# AE1C1F4051920PH0_CM55_HE_View register map
Vendor: Alif Semiconductor; Series: E1; File version: 1.0
CPU: CM55 r1p0, selectable endian, MPU, FPU, double-precision FPU, DSP, VTOR, 8 interrupt priority bits, 1 SAU regions
Registers are 32-bit, read-write, reset 0x0 unless marked. A register's access mark holds for its fields unless they carry their own. Offsets are from the block's base; [hi:lo] are bit positions; {n}, {i} and the like mark numbered series; <NAME> marks a mode.

## CANFD0
Base 0x49036000
Same registers: CANFD1 0x49038000
{0x0+4i} CANFD_RBUF[{i}] (i=0..19) ro — Receive Buffer Register
  [31:0] RBUF
{0x50+4i} CANFD_TBUF[{i}] (i=0..17) — Transmit Buffer Register
  [31:0] TBUF
0x98 CANFD_TTS ro — Transmission Time Stamp Register
  [31:0] TTS — Transmission Time Stamp. This bit field holds the time-stamp of the last transmitted frame for CiA 603 time stamping. Every new frame overwrites it if the TTSEN field of TBUF register is 0x1. The TTS bit field is intended to be used by the time master to acquire the time-stamp of the SYNC message.
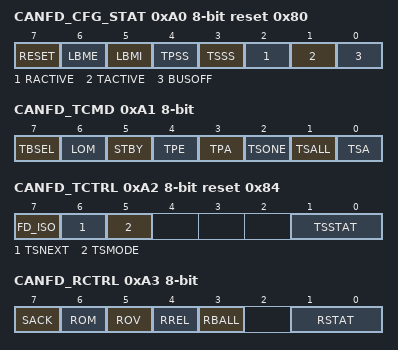
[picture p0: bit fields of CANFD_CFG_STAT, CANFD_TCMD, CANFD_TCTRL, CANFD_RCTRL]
0xA0 CANFD_CFG_STAT 8-bit reset 0x80 — Configuration and Status Register
  [7] RESET — RESET Request Bit. Some registers can only be modified if the RESET bit is set to 0x1. This bit forces several components to a reset state. A detailed definition is given in Section Software Reset. It is automatically set if the node enters bus off state (refer to Section Error Handling). Note that a CAN node will participate in CAN communication after the RESET bit is switched to 0x0 after 11 CAN bit times. This delay is required by the CAN standard (bus idle time). If the RESET bit is set to 0x1 and immediately set to 0x0, then it takes some time until it can be read as 0x0 and becomes inactive. The reason is clock domain crossing from host to CAN clock domain. The RESET bit is held active as long as needed depending on the relation between host and CAN clock.
    0=No local reset of the CAN controller; 1=The host controller performs a local reset of the CAN controller
  [6] LBME — Loop Back Mode, External (refer to Section Loop Back Mode (LBMI and LBME)). Note that this bit should not be enabled while a transmission is active.
    0=Disabled; 1=Enabled
  [5] LBMI — Loop Back Mode, Internal (refer to Section Loop Back Mode (LBMI and LBME)). Note that this bit should not be enabled while a transmission is active.
    0=Disabled; 1=Enabled
  [4] TPSS — Transmission Primary Single Shot Mode for PTB (refer to Section Single Shot Transmission (SST)).
    0=Disabled; 1=Enabled
  [3] TSSS — Transmission Secondary Single Shot Mode for STB (refer to Section Single Shot Transmission (SST)).
    0=Disabled; 1=Enabled
  [2] RACTIVE ro — Reception ACTIVE (Receive Status Bit).
    0=No receive activity; 1=The controller is currently receiving a frame
  [1] TACTIVE ro — Transmission ACTIVE (Transmit Status Bit).
    0=No transmit activity; 1=The controller is currently transmitting a frame
  [0] BUSOFF — Bus Off (Bus Status Bit, refer to Section Error Handling). Writing a 0x1 to this bit will reset the CANFD_TECNT and CANFD_RECNT registers. This should be done only for debugging. For more details, refer Section Error Counter Reset.
    0=The controller status is bus on; 1=The controller status is bus off
0xA1 CANFD_TCMD 8-bit — Command Register
  [7] TBSEL — Transmit Buffer Select. Selects the transmit buffer to be loaded with a message. Use the TBUF registers for access. The TBSEL bit needs to be stable all the time the TBUF registers are written and when the CANFD_TCTRL[TSNEXT] bit is set.
    0=PTB (high-priority buffer); 1=STB
  [6] LOM — Listen Only Mode (refer to Section Listen Only Mode (LOM)). This bit cannot be set if the TPE, TSONE, or TSALL bit is set. No transmission can be started if it is enabled and the CANFD_CFG_STAT[LBME] bit is disabled. The LOM = 0x1 and CANFD_CFG_STAT[LBME] = 0x0 disables all transmissions. The LOM = 0x1 and CANFD_CFG_STAT[LBME] = 0x1 disables the ACK for received frames and error frames, but enables the transmission of own frames.
    0=Disabled; 1=Enabled
  [5] STBY — Transceiver Standby Mode (refer to Section Transceiver Standby Mode). This register bit can be used to control a standby mode of a transceiver. This bit cannot be set to 0x1 if the TPE, TSONE, or TSALL bit is set to 0x1. If the host sets it to 0x0 then the host needs to wait for the time required by the transceiver to start up before the host requests a new transmission.
    0=Disabled; 1=Enabled
  [4] TPE — Transmit Primary Enable. If this bit is set, the message from the PTB will be transmitted at the next possible transmit position. A started transmission from the STB will be completed before, but pending new messages are delayed until the PTB message has been transmitted. The TPE bit stays set until the message has been transmitted successfully or it is aborted using the TPA bit. The host controller can set the TPE bit to 0x1 but can not reset it to 0x0. This would only be possible using the TPA bit and aborting the message. The bit will be reset to the hardware reset value if the CANFD_CFG_STAT[RESET] = 0x1, STBY = 0x1, (LOM = 0x1 and CANFD_CFG_STAT[LBME] = 0x0).
    0=No transmission for the PTB; 1=Transmission enable for the message in the high-priority PTB
  [3] TPA — Transmit Primary Abort. The bit has to be set by the host controller and will be reset by the CAN controller. Setting this bit automatically de-asserts the TPE bit. The host controller can set the TPA bit to 0x1 but can not reset it to 0x0. During the short time while the CAN controller resets the bit, it cannot be set by the host. The bit will be reset to the hardware reset value if the CANFD_CFG_STAT[RESET] = 0x1. This bit should not be set simultaneously with the TPE bit.
    0=No abort; 1=Aborts a transmission from PTB which has been requested by the TPE = 0x1 but not started yet (the data bytes of the message remains in the PTB)
  [2] TSONE — Transmit Secondary One Frame. This bit in priority mode is difficult to handle, because it is not always clear which message will be transmitted if new messages are written to the STB meanwhile. The controller starts the transmission as soon as the bus becomes vacant and no request of the PTB (the TPE bit) is pending. The TSONE bit stays set until the message has been transmitted successfully or it is aborted using the TSA bit. The host controller can set the TSONE bit to 0x1 but can not reset it to 0x0. This would only be possible using the TSA bit and aborting the message. The bit will be reset to the hardware reset value if the CANFD_CFG_STAT[RESET] = 0x1, STBY = 0x1, (LOM = 0x1 and CANFD_CFG_STAT[LBME] = 0x0).
    0=No transmission for the STB; 1=Transmission enable of one in the STB. In FIFO mode this is the oldest message and in priority mode this is the one with the highest priority
  [1] TSALL — Transmit Secondary All Frames. The controller starts the transmission as soon as the bus becomes vacant and no request of the PTB (the TPE bit) is pending. This bit stays set until all messages have been transmitted successfully or they are aborted using the TSA bit. The host controller can set the TSALL bit to 0x1 but can not reset it to 0x0. This would only be possible using the TSA bit and aborting the messages. The bit will be reset to the hardware reset value if the CANFD_CFG_STAT[RESET] = 0x1, STBY = 0x1, (LOM = 0x1 and CANFD_CFG_STAT[LBME] = 0x0). If during a transmission the STB is loaded with a new frame then the new frame will be transmitted too. In other words: a transmission initiated by this bit is finished when the STB becomes empty. Note: Setting both TSONE and TSALL bits is meaningless. While the TSALL bit is already set, it is impossible to set the TSONE bit and vice versa. If both TSONE and TSALL bits are set simultaneously then the TSALL bit wins and the TSONE bit is cleared by the CAN controller.
    0=No transmission for the STB; 1=Transmission enable of all messages in the STB
  [0] TSA — Transmit Secondary Abort. The bit has to be set by the host controller and will be reset by the CAN controller. Setting this bit, automatically de-asserts the TSONE or TSALL bit respectively. The host controller can set this bit to 0x1 but can not reset it to 0x0. The bit will be reset to the hardware reset value if the CANFD_CFG_STAT[RESET] = 0x1. This bit should not be set simultaneously with the TSONE or TSALL bit. For a TSONE transmission, only one frame is aborted while for a TSALL transmission, all frames are aborted. One or all message slots will be released which updates the CANFD_TCTRL[TSSTAT] bit field. All aborted messages are lost because they are not accessible any more. If in priority mode a TSONE transmission is aborted, then it is not clear which frame will be aborted if new frames are written to the STB meanwhile.
    0=No abort; 1=Aborts a transmission from STB which has been requested but not started yet
0xA2 CANFD_TCTRL 8-bit reset 0x84 — Transmit Control Register
  [7] FD_ISO — CAN FD ISO Mode. ISO CAN FD mode has a different CRC initialization value and an additional stuff bit count. Both modes are incompatible and must not be mixed in one CAN network. This bit has no impact to CAN 2.0B. This bit is only writeable if the CANFD_CFG_STAT[RESET] = 0x1.
    0=Bosch CAN FD (non-ISO) mode; 1=ISO CAN FD mode (ISO 11898-1:2015)
  [6] TSNEXT — Transmit Buffer Secondary Next. After all frame bytes are written to the TBUF registers, the host controller has to set this bit to signal that this slot has been filled. Then the CAN controller connects the TBUF registers to the next slot. Once a slot is marked as filled a transmission can be started using the CANFD_TCMD[TSONE] or CANFD_TCMD[TSALL] bit. It is possible to set the TSNEXT bit and the CANFD_TCMD[TSONE] or CANFD_TCMD[TSALL] bit together in one write access. This bit has to be set by the host controller and is automatically reset by the CAN controller immediately after it was set. Setting the TSNEXT bit is meaning less if the CANFD_TCMD[TBSEL] = 0x0. In this case the TSNEXT bit is ignored and automatically cleared. It does not do any harm. If all slots of the STB are filled, this bit stays set until a slot becomes free (refer to Section Full STB).
    0=No action; 1=STB slot filled, select next slot
  [5] TSMODE — Transmit Buffer Secondary Operation Mode. In FIFO mode frames are transmitted in the order in that they are written into the STB. In priority decision mode the frame with the highest priority in the STB is automatically transmitted first. The ID of a frame is used for the priority decision. A lower ID means a higher priority of a frame. A frame in the PTB has always the highest priority regardless of the ID. This bit shall be switched only if the STB is empty.
    0=FIFO mode; 1=Priority decision mode
  [1:0] TSSTAT ro — Transmission Secondary Status Bits.
    0=STB is empty; 1=STB is less than or equal to half full; 2=STB is more than half full; 3=STB is full
0xA3 CANFD_RCTRL 8-bit — Receive Control Register
  [7] SACK — Self-Acknowledge.
    0=No self-ACK; 1=Self-ACK when the CANFD_CFG_STAT[LBME] = 0x1
  [6] ROM — Receive Buffer Overflow Mode. In case of a full RBUF when a new message is received, then this bit selects the following:
    0=The oldest message will be overwritten; 1=The new message will not be stored
  [5] ROV ro — Receive Buffer Overflow. This bit is cleared by setting the RREL = 0x1.
    0=No Overflow; 1=Overflow. At least one message is lost
  [4] RREL — Receive Buffer Release. The host controller has read the actual RB slot and releases it. Afterwards the CAN controller points to the next RB slot. The RSTAT bit field gets updated.
    0=No release; 1=Release: The host has read the RB
  [3] RBALL — Receive Buffer Stores All Data Frames.
    0=Normal operation; 1=RB stores correct data frames as well as data frames with error (refer to Section Reception of All Data Frames (CANFD_RCTRL[RBALL]))
  [1:0] RSTAT ro — Receive Buffer Status.
    0=Empty; 1=> Empty and < almost full (CANFD_LIMIT[AFWL]); 2=Almost full (programmable threshold by the CANFD_LIMIT[AFWL] bit field) but not full and no overflow; 3=Full (stays set in case of overflow-for overflow signaling, see the ROV bit)
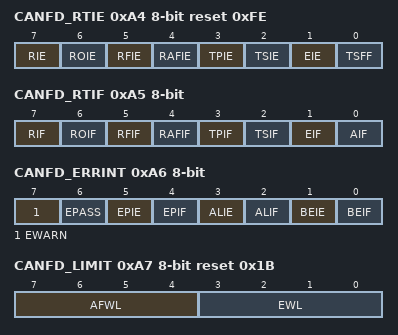
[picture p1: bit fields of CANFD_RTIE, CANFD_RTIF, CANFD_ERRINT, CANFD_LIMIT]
0xA4 CANFD_RTIE 8-bit reset 0xFE — Receive and Transmit Interrupt Enable Register
  [7] RIE — Receive Interrupt Enable.
    0=Disabled; 1=Enabled
  [6] ROIE — RB Overrun Interrupt Enable.
    0=Disabled; 1=Enabled
  [5] RFIE — RB Full Interrupt Enable.
    0=Disabled; 1=Enabled
  [4] RAFIE — RB Almost Full Interrupt Enable.
    0=Disabled; 1=Enabled
  [3] TPIE — Transmission Primary Interrupt Enable.
    0=Disabled; 1=Enabled
  [2] TSIE — Transmission Secondary Interrupt Enable.
    0=Disabled; 1=Enabled
  [1] EIE — Error Interrupt Enable.
    0=Disabled; 1=Enabled
  [0] TSFF ro — Transmit Secondary Buffer Full Flag.
    0=The STB is not filled with the maximal number of messages; 1=The STB is filled with the maximal number of messages
0xA5 CANFD_RTIF 8-bit — Receive and Transmit Interrupt Flag Register
  [7] RIF write-1-clears — Receive Interrupt Flag.
    0=No frame has been received; 1=Data or a remote frame has been received and is available in the receive buffer
  [6] ROIF write-1-clears — RB Overrun Interrupt Flag. In case of an overrun both ROIF and RFIF bits are set.
    0=No RB overwritten; 1=At least one received message has been overwritten in the RB
  [5] RFIF write-1-clears — RB Full Interrupt Flag.
    0=The RB FIFO is not full; 1=All RBs are full. If no RB is released until the next valid message is received, the oldest message is lost
  [4] RAFIF write-1-clears — RB Almost Full Interrupt Flag. Refer to the CANFD_LIMIT[AFWL] bit field.
    0=number of filled RB slots < AFWL_i; 1=number of filled RB slots AFWL_i
  [3] TPIF write-1-clears — Transmission Primary Interrupt Flag.
    0=No transmission of the PTB has been completed; 1=The requested transmission of the PTB has been successfully completed
  [2] TSIF write-1-clears — Transmission Secondary Interrupt Flag.
    0=No transmission of the STB has been completed successfully; 1=The requested transmission of the STB has been successfully completed
  [1] EIF write-1-clears — Error Interrupt Flag.
    0=There has been no change; 1=The border of the error warning limit has been crossed in either direction, or the CANFD_CFG_STAT[BUSOFF] bit has been changed in either direction
  [0] AIF write-1-clears — Abort Interrupt Flag. It is recommended to not set both CANFD_TCMD[TPA] and CANFD_TCMD[TSA] bits simultaneously because both source this bit. This bit does not have an associated enable register. Refer to Section Message Transmission Abort.
    0=No abort has been executed; 1=After setting the CANFD_TCMD[TPA] or CANFD_TCMD[TSA] bit the appropriated message(s) have been aborted
0xA6 CANFD_ERRINT 8-bit — Error Interrupt Enable and Flag Register
  [7] EWARN ro — Error Warning Limit Reached.
    0=The values in both counters are less than the CANFD_LIMIT[EWL] bit field; 1=One of the error counters (the CANFD_RECNT or CANFD_TECNT register) is equal or bigger than the CANFD_LIMIT[EWL] bit field
  [6] EPASS ro — Error Passive Mode Active.
    0=Not active (node is error active); 1=Active (node is error passive)
  [5] EPIE — Error Passive Interrupt Enable.
  [4] EPIF write-1-clears — Error Passive Interrupt Flag. This bit will be activated if the error status changes from error active to error passive or vice versa and if this interrupt is enabled.
  [3] ALIE — Arbitration Lost Interrupt Enable.
  [2] ALIF write-1-clears — Arbitration Lost Interrupt Flag.
  [1] BEIE — Bus Error Interrupt Enable.
  [0] BEIF write-1-clears — Bus Error Interrupt Flag.
0xA7 CANFD_LIMIT 8-bit reset 0x1B — Warning Limits Register
  [7:4] AFWL — Almost Full Warning Limit. The AFWL bit field defines the internal warning limit AFWL_i with nRB being the number of available RB slots. AFWL_i is compared to the number of filled RB slots and triggers the CANFD_RTIF[RAFIF] bit if equal. The valid range of AFWL_i is [1KB nRB]. AFWL = 0 is meaningless and automatically treated as 0x1. Note that AFWL is meant in this rule and not AFWL_i. AFWL_i > nRB is meaningless and automatically treated as nRB. AFWL_i = nRB is a valid value, but note that the CANFD_RTIF[RFIF] bit also exists.
  [3:0] EWL — Programmable Error Warning Limit = (EWL + 1) x 8. Possible Limit values: 8, 16, ...128. The value of this bit field controls the CANFD_RTIF[EIF] bit. The EWL bit field needs to be transferred using Clock Domain Crossing (CDC) from host to CAN clock domain. During transfer, this bit field is write-locked for the host for a few clocks until CDC is complete.
0xA8 CANFD_S_SEG_1 8-bit reset 0x3 — Slow Speed Bit Timing 1 Register (Segment 1)
  [7:0] S_SEG_1 — Bit Timing Segment 1 (Slow Speed). The sample point will be set to tSeg_1 = (Seg_1 + 2) x TQ after start of bit time.
0xA9 CANFD_S_SEG_2 8-bit reset 0x2 — Slow Speed Bit Timing 2 Register (Segment 2)
  [6:0] S_SEG_2 — Bit Timing Segment 2 (Slow Speed). Time tSeg_2 = (Seg_2 + 1) x TQ after the sample point.
0xAA CANFD_S_SJW 8-bit reset 0x2 — Slow Speed Bit Timing 3 Register (Synchronization Jump Width)
  [6:0] S_SJW — Synchronization Jump Width (Slow Speed). The Synchronization Jump Width tSJW = (SJW + 1) x TQ is the maximum time for shortening or lengthening the Bit Time for resynchronization, where TQ is a time quanta.
0xAB CANFD_S_PRESC 8-bit reset 0x1 — Slow Speed Prescaler Register
  [7:0] S_PRESC — Prescaler Slow Speed. The prescaler divides the system clock to get the time quanta clock. Valid range for the CANFD_S_PRESC[S_PRESC] bit field is from 0x00 to 0xFF (results in divider values from 1 to 255).
0xAC CANFD_F_SEG_1 8-bit reset 0x3 — Fast Speed Bit Timing 1 Register (Segment 1)
  [4:0] F_SEG_1 — Bit Timing Segment 1 (Fast Speed). The sample point will be set to tSeg_1 = (Seg_1 + 2) x TQ after start of bit time.
0xAD CANFD_F_SEG_2 8-bit reset 0x2 — Fast Speed Bit Timing 2 Register (Segment 2)
  [3:0] F_SEG_2 — Bit Timing Segment 2 (Fast Speed). Time tSeg_2 = (Seg_2 + 1) x TQ after the sample point.
0xAE CANFD_F_SJW 8-bit reset 0x2 — Fast Speed Bit Timing 3 Register (Synchronization Jump Width)
  [3:0] F_SJW — Synchronization Jump Width (Fast Speed). The Synchronization Jump Width tSJW = (SJW + 1) x TQ is the maximum time for shortening or lengthening the Bit Time for resynchronization, where TQ is a time quanta.
0xAF CANFD_F_PRESC 8-bit reset 0x1 — Fast Speed Prescaler Register
  [7:0] F_PRESC — Prescaler Fast Speed. The prescaler divides the system clock to get the time quanta clock. Valid range for the CANFD_F_PRESC[F_PRESC] bit field is from 0x00 to 0xFF (results in divider values from 1 to 255).
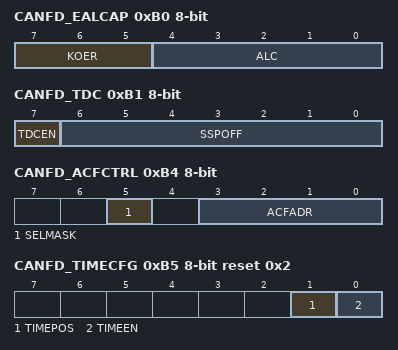
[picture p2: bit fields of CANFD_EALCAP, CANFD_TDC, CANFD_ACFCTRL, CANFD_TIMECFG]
0xB0 CANFD_EALCAP 8-bit ro — Error and Arbitration Lost Capture Register
  [7:5] KOER — Kind of Error (Error Code). (dominant bits after own error flag, received active Error Flag too long, dominant bit during Passive-Error-Flag after ACK error) This bit field is updated with each new error. Therefore, it stays untouched when frames are successfully transmitted or received.
    0=No error; 1=BIT ERROR; 2=FORM ERROR; 3=STUFF ERROR; 4=ACKNOWLEDGEMENT ERROR; 5=CRC ERROR; 6=OTHER ERROR
  [4:0] ALC — Arbitration Lost Capture (bit position in the frame where the arbitration has been lost)
0xB1 CANFD_TDC 8-bit — Transmitter Delay Compensation Register
  [7] TDCEN — Transmitter Delay Compensation Enable. The Transmitter Delay Compensation (TDC) will be activated during the data phase of a CAN FD frame if BRS is active and if the TDCEN = 0x1. For more details about TDC refer to Section Bit Rate Switching and Sample Point.
  [6:0] SSPOFF — Secondary Sample Point Offset. The transmitter delay plus defines the time of the secondary sample point for TDC (the SSPOFF bit field value is given as a number of TQ).
0xB2 CANFD_RECNT 8-bit ro — Receive Error Counter Register
  [7:0] RECNT — Receive Error Count (Number of Errors During Reception). This bit field is incremented and decremented as defined in the CAN specification. The CANFD_RECNT register does not overflow. For more details about the CANFD_RECNT register and the bus off state, refer to Section Error Handling.
0xB3 CANFD_TECNT 8-bit ro — Transmit Error Counter Register
  [7:0] TECNT — Transmit Error Count (Number of Errors During Transmission). This bit field is incremented and decremented as defined in the CAN specification. In case of the bus off state, the TECNT bit field may overflow. For more details about this bit field and the bus off state, refer to Section Error Handling.
0xB4 CANFD_ACFCTRL 8-bit — Acceptance Filter Control Register
  [5] SELMASK — Select Acceptance MASK. The ACFADR bit field selects one specific acceptance filter.
    0=The ACF_X registers (where X = 1 to 3) point to acceptance code; 1=The ACF_X registers (where X = 1 to 3) point to acceptance mask
  [3:0] ACFADR — Acceptance Filter Address. This bit field points to a specific acceptance filter. The selected filter is accessible using the ACF_X registers (where X = 1 to 3). The SELMASK bit selects between acceptance code and mask for the selected acceptance filter. A value of the ACFADR bit field > Number of Acceptance Filters (NAF) - 1 is meaningless and automatically treated as value NAF - 1.
0xB5 CANFD_TIMECFG 8-bit reset 0x2 — CiA 603 Time-Stamping Register
  [1] TIMEPOS — Time-Stamping Position. For description of the SOF and EOF bits, refer to Section Table 1-2 CAN Bit Abbreviations. This bit can only be changed if the TIMEEN = 0x0, but it is possible to modify it with the same write access that sets the TIMEEN = 0x1.
    0=SOF; 1=EOF
  [0] TIMEEN — Time-Stamping Enable.
    0=Disabled; 1=Enabled
0xB6 CANFD_ACF_EN_0 8-bit reset 0x1 — Acceptance Filter Enable 0 Register
  [7:0] AE_X — Acceptance Filter Enable. Each acceptance filter (AMASK/ACODE) can be individually enabled or disabled. Only filter number 0 is enabled by default after hardware reset. Disabled filters reject a message. Only enabled filters can accept a message if the appropriate AMASK/ACODE configuration matches. To accept all messages one filter x has to be enabled by setting AE_X = 0x1, AMASK_X = 0xFF and ACODE_X = 0x00. This is the default configuration after hardware reset for filter X = 0 while all other filters are disabled.
    0=Acceptance filter disable; 1=Acceptance filter enabled
0xB7 CANFD_ACF_EN_1 8-bit — Acceptance Filter Enable 1 Register
  [7:0] AE_X — Acceptance Filter Enable. Each acceptance filter (AMASK/ACODE) can be individually enabled or disabled. Disabled filters reject a message. Only enabled filters can accept a message if the appropriate AMASK/ACODE configuration matches.
    0=Acceptance filter disable; 1=Acceptance filter enabled
0xB8 CANFD_ACF_0_3_CODE — Acceptance CODE Register
  [28:0] ACODE_X — Acceptance CODE. The ID bits are compared with the corresponding acceptance code bits as follows: - ACODE_X(10-0) will be used for standard frames. - ACODE_X(28-0) will be used for extended frames. Only filter 0 is affected by the power-on reset. All other filters stay uninitialized. Refer to Section Software Reset.
    0=Acceptance code bit value to compare with ID bit of the received message is disabled; 1=Acceptance code bit value to compare with ID bit of the received message is enabled
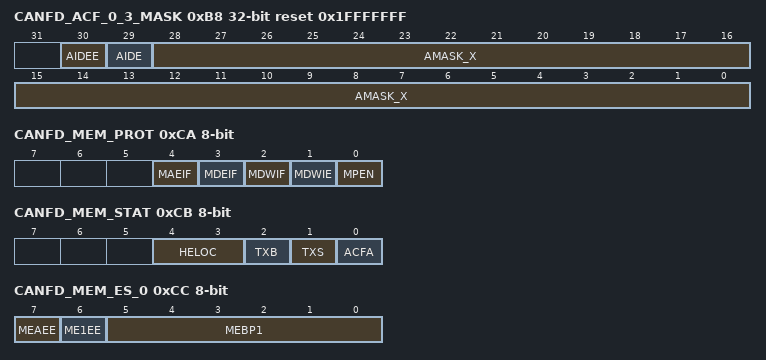
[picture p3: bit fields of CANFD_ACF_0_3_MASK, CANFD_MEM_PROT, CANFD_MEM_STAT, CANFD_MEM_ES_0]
0xB8 CANFD_ACF_0_3_MASK reset 0x1FFFFFFF (alternate view of CANFD_ACF_0_3_CODE) — Acceptance MASK Register
  [30] AIDEE — Acceptance Mask IDE Bit Check Enable. Only filter 0 is affected by the power-on reset. All other filters stay uninitialized.
    0=Acceptance filter accepts both standard or extended frames; 1=Acceptance filter accepts either standard or extended as defined by this bit
  [29] AIDE — Acceptance Mask IDE Bit Value. If the AIDEE = 0x1 then: Only filter 0 is affected by the power-on reset. All other filters stay uninitialized. Note: The AIDEE and AIDE bits can only be accessed if the CANFD_ACFCTRL[SELMASK] = 0x1. These bits can be used to accept only either standard or extended frames with the selected ACODE / AMASK setting or to accept both frame types. Only acceptance filter 0 is affected by the power-on reset and it is configured to accept both frame types after power-up.
    0=Acceptance filter accepts only standard frames; 1=Acceptance filter accepts only extended frames
  [28:0] AMASK_X — Acceptance MASK 3. - AMASK_X(10-0) will be used for standard frames. - AMASK_X(28-0) will be used for extended frames. Disabled bits result in accepting the message. Therefore, the default configuration after reset for filter 0 accepts all messages. Only filter 0 is affected by the power-on reset. All other filters stay uninitialized. Refer to Section Software Reset.
    0=Acceptance check for these bits of receive identifier enable; 1=Acceptance check for these bits of receive identifier disabled
0xBC CANFD_VER_0 8-bit ro reset 0x9 — Version Information 0 Register
  [7:0] VER_0 — Version (minor) [7-0]
0xBD CANFD_VER_1 8-bit ro reset 0x7 — Version Information 1 Register
  [7:0] VER_1 — Version (major) [15-0]
0xCA CANFD_MEM_PROT 8-bit — Memory Protection Register
  [4] MAEIF — Memory: Address Error Interrupt Flag. This bit will be set if memory protection has detected an error in the address. The error was not corrected.
  [3] MDEIF — Memory: Data Error Interrupt Flag. This bit will be set if memory protection has detected an error in the data which was not correctable.
  [2] MDWIF — Memory: Data Warning Interrupt Flag. This bit will be set if the MDWIE bit is set and memory protection has detected an error in the data which has been automatically corrected. The system continues operation.
  [1] MDWIE — Memory: Data Warning Interrupt Enable.
    0=Disabled; 1=Enabled
  [0] MPEN — Memory Protection Enable. This bit is only writable if the CANFD_CFG_STAT[RESET] = 0x1.
    0=Disabled; 1=Enabled
0xCB CANFD_MEM_STAT 8-bit — Memory Status Register
  [4:3] HELOC ro — Host Side Memory Error Location. This bit field will be updated with every new error during a read access from the host side. This is sufficient, because read errors during read accesses from the CAN side will be signaled by the ACFA, TXS and TXB bits. The HELOC bit field will only be updated in case of an error, but not in case of a warning caused by a corrected single bit error.
    0=No error during access from host side; 1=Error during access from host side in TBUF; 2=Error during access from host side in RBUF; 3=Error during access from host side in ACF
  [2] TXB ro — Transmission Block. If the CANFD_MEM_PROT[MDEIF] or CANFD_MEM_PROT[MAEIF] bit is set because of an error while the CAN protocol machine is reading data for transmission, then the transmission is immediately blocked. If the CANFD_SRCFG[SREIF] bit is set, then the transmission is immediately blocked too. The TXB bit is reset if the CANFD_CFG_STAT[RESET] = 0x1.
    0=Normal operation; 1=Transmission blocked
  [1] TXS ro — Transmission Stop. If the CANFD_MEM_PROT[MDEIF] or CANFD_MEM_PROT[MAEIF] bit is set because of an error while the priority reordering machine accesses the memory, then any new transmission is stopped. If there is an active transmission, this will be completed before the stop, but if an error occurs during this transmission then no retransmission will be started. The TXS bit is reset if the CANFD_CFG_STAT[RESET] = 0x1.
    0=Normal operation; 1=Transmission stopped
  [0] ACFA — Acceptance Filter Accept. If the CANFD_MEM_PROT[MDEIF] or CANFD_MEM_PROT[MAEIF] bit is set because of an error in the address range of the ACF, this bit is set. Then acceptance filtering is disabled and all frames will be accepted. The ACFA bit can be reset similar to an interrupt flag by writing a 0x1 to it. But because it will be set while the reception is still active, it is required to reset if later after the reception has been completed and the CANFD_RTIF[RIF] bit has been set. This bit is also reset if the CANFD_CFG_STAT[RESET] = 0x1.
    0=Normal operation of ACF; 1=ACF disabled: all received frames are accepted
0xCC CANFD_MEM_ES_0 8-bit — Memory Error Stimulation 0 Register
  [7] MEAEE — Memory Error: Address Error Enable. If the MEAEE = 0x1 then the address bit 2 is flipped. The result is an access to the neighbor 32 bit word. The error is only triggered for the access defined by the CANFD_MEM_ES_2[MEEEC], CANFD_MEM_ES_2[MENEC], CANFD_MEM_ES_3[MEL] bit fields and the CANFD_MEM_ES_3[MES] bit.
    0=Disabled; 1=Enabled
  [6] ME1EE — Memory Error: 1^st Error Enable. If ME1EE = 0x1 then the MEBP1 bit field is used to do stimulation of a single bit error. To stimulate a dual bit error, the CANFD_MEM_ES_1[MEBP2] bit field and the CANFD_MEM_ES_1[ME2EE] bit needs to be used too. The error is only triggered for the access defined by the CANFD_MEM_ES_2[MEEEC], CANFD_MEM_ES_2[MENEC], CANFD_MEM_ES_3[MEL] bit fields and the CANFD_MEM_ES_3[MES] bit.
    0=Disabled; 1=Enabled
  [5:0] MEBP1 — Memory Error: Bit Position 1. This bit field defines the position of one single bit error during memory read.
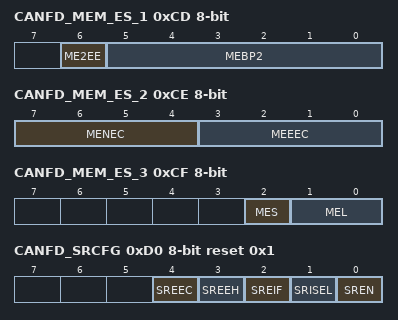
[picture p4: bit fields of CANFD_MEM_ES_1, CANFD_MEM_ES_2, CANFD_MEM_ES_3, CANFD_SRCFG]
0xCD CANFD_MEM_ES_1 8-bit — Memory Error Stimulation 1 Register
  [6] ME2EE — Memory Error: 2^nd Error Enable. If the ME2EE = 0x1 then the MEBP2 bit field is used to do stimulation of a single bit error. The error is only triggered for the access defined by the CANFD_MEM_ES_2[MEEEC], CANFD_MEM_ES_2[MENEC], CANFD_MEM_ES_3[MEL] bit fields and the CANFD_MEM_ES_3[MES] bit.
    0=Disabled; 1=Enabled
  [5:0] MEBP2 — Memory Error: Bit Position 2. This bit field defines the position of one single bit error during memory read. To stimulate a dual bit error, the CANFD_MEM_ES_0[MEBP1] bit field and the CANFD_MEM_ES_0[ME1EE] bit needs to be used too.
0xCE CANFD_MEM_ES_2 8-bit — Memory Error Stimulation 2 Register
  [7:4] MENEC — Memory Error: No Error Counter. Error stimulation is delayed if the MEEEC bit field value > 0. The MEEEC bit field value is automatically decremented after each memory read access (defined by the CANFD_MEM_ES_3[MEL] bit field and the CANFD_MEM_ES_3[MES] bit) until it reaches the value 0x0.
  [3:0] MEEEC — Memory Error: Error Enable Counter. Error stimulation is activated if the MENEC = 0x0 and the MEEEC bit field value > 0. This bit field is automatically decremented after each event of an error stimulation (defined by the CANFD_MEM_ES_3[MEL] bit field and the CANFD_MEM_ES_3[MES] bit) until it reaches the value 0x0.
0xCF CANFD_MEM_ES_3 8-bit — Memory Error Stimulation 3 Register
  [2] MES — Memory Error Side. This bit defines the side which will be hit by the next memory error together with the MEL bit field.
    0=Host side; 1=CAN side
  [1:0] MEL — Memory Error Location. This bit field defines the memory area which will be hit by the next memory error together with the MES bit.
    0=ACF; 1=TBUF; 2=RBUF; 3=ACF
0xD0 CANFD_SRCFG 8-bit reset 0x1 — Spatial Redundancy Configuration Register
  [4] SREEC — Spatial Redundancy: Error Enable in CANFD_CLK Domain. If the SREEC = 0x1 and SREN = 0x1, then output signal is flipped in the instance defined by the SRISEL bit. This results in a difference between the two instances which will be detected by the logic checker.
    0=No error stimulation; 1=Error stimulation
  [3] SREEH — Spatial Redundancy: Error Enable in CANFD_HOST_CLK Domain. If the SREEH = 0x1 and SREN = 0x1, then VERSION(15) is flipped in the instance defined by the SRISEL bit. As a consequence a read access to VERSION results in a difference between the two instances which will be detected by the logic checker.
    0=No error stimulation; 1=Error stimulation
  [2] SREIF — Spatial Redundancy: Error Interrupt Flag. If the SREN = 0x1 and if there is a severe mismatch between both instances of the logic core of the CAN controller then the SREIF and CANFD_MEM_STAT[TXB] bits will be set.
    0=No interrupt; 1=Interrupt pending
  [1] SRISEL — Spatial Redundancy: Instance Selection. If the SREN= 0x0 then this bit selects the instance, that is used for operation. The SRISEL bit can only be modified if the CANFD_CFG_STAT[RESET] = 0x1.
  [0] SREN — Spatial Redundancy: Enable. If enabled, then two instances of the logic core of the CAN controller are compared at runtime to each other. If this comparison is disabled then one of the two instances is used for operation as defined by the SRISEL bit. This bit can only be modified if the CANFD_CFG_STAT[RESET] = 0x1.
    0=Disabled; 1=Enabled
